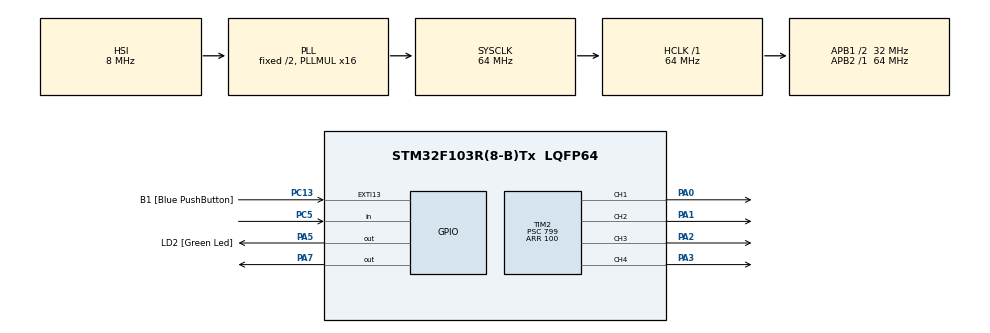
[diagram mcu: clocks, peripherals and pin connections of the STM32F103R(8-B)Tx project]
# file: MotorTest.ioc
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Mcu.Family=STM32F1
TIM2.Channel-PWM\ Generation4\ CH4=TIM_CHANNEL_4
PA14.GPIO_Label=TCK
PC13-TAMPER-RTC.Signal=GPXTI13
TIM2.Channel-PWM\ Generation2\ CH2=TIM_CHANNEL_2
RCC.APB1CLKDivider=RCC_HCLK_DIV2
RCC.SYSCLKSource=RCC_SYSCLKSOURCE_PLLCLK
ProjectManager.StackSize=0x400
PA0-WKUP.Signal=S_TIM2_CH1_ETR
TIM2.Pulse-PWM\ Generation1\ CH1=60
PA13.Signal=SYS_JTMS-SWDIO
SH.S_TIM2_CH2.0=TIM2_CH2,PWM Generation2 CH2
ProjectManager.TargetToolchain=STM32CubeIDE
RCC.HCLKFreq_Value=64000000
RCC.APB2TimFreq_Value=64000000
RCC.USBFreq_Value=64000000
PA1.Signal=S_TIM2_CH2
RCC.AHBFreq_Value=64000000
NVIC.EXTI15_10_IRQn=true\:0\:0\:false\:false\:true\:true\:true
PA5.Signal=GPIO_Output
board=NUCLEO-F103RB
RCC.RTCClockSelection=RCC_RTCCLKSOURCE_LSE
PC13-TAMPER-RTC.GPIO_Label=B1 [Blue PushButton]
RCC.PLLMUL=RCC_PLL_MUL16
RCC.APB2Freq_Value=64000000
PA5.GPIO_ModeDefaultOutputPP=GPIO_MODE_OUTPUT_PP
VP_TIM2_VS_ClockSourceINT.Mode=Internal
SH.S_TIM2_CH3.0=TIM2_CH3,PWM Generation3 CH3
PA14.Mode=Serial_Wire
PA5.GPIO_PuPd=GPIO_NOPULL
TIM2.Channel-PWM\ Generation3\ CH3=TIM_CHANNEL_3
TIM2.Channel-PWM\ Generation1\ CH1=TIM_CHANNEL_1
TIM2.Period=100
PA13.Mode=Serial_Wire
Mcu.Name=STM32F103R(8-B)Tx
PA2.Signal=S_TIM2_CH3
PA13.GPIO_Label=TMS
RCC.SYSCLKFreq_VALUE=64000000
Mcu.Package=LQFP64
TIM2.Prescaler=799
PA5.GPIO_Label=LD2 [Green Led]
PC13-TAMPER-RTC.GPIO_PuPd=GPIO_NOPULL
SH.S_TIM2_CH1_ETR.0=TIM2_CH1,PWM Generation1 CH1
PA14.Signal=SYS_JTCK-SWCLK
ProjectManager.HeapSize=0x200
SH.S_TIM2_CH4.0=TIM2_CH4,PWM Generation4 CH4
TIM2.Pulse-PWM\ Generation2\ CH2=60
PA5.GPIO_Speed=GPIO_SPEED_FREQ_LOW
NVIC.PriorityGroup=NVIC_PRIORITYGROUP_4
RCC.APB1TimFreq_Value=64000000
PC5.Signal=GPIO_Input
RCC.APB1Freq_Value=32000000
PA3.Signal=S_TIM2_CH4
PA7.Signal=GPIO_Output

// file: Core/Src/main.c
/* USER CODE BEGIN Header */
/**
  ******************************************************************************
  * @file           : main.c
  * @brief          : Main program body
  ******************************************************************************
  * @attention
  *
  * <h2><center>&copy; Copyright (c) 2021 STMicroelectronics.
  * All rights reserved.</center></h2>
  *
  * This software component is licensed by ST under BSD 3-Clause license,
  * the "License"; You may not use this file except in compliance with the
  * License. You may obtain a copy of the License at:
  *                        opensource.org/licenses/BSD-3-Clause
  *
  ******************************************************************************
  */
/* USER CODE END Header */
#include "main.h"

TIM_HandleTypeDef htim2;

void SystemClock_Config(void);
static void MX_GPIO_Init(void);
static void MX_TIM2_Init(void);
/* USER CODE BEGIN PFP */
void Delay(uint32_t count);
/* USER CODE END PFP */

int main(void)
{

  /* MCU Configuration--------------------------------------------------------*/

  /* Reset of all peripherals, Initializes the Flash interface and the Systick. */
  HAL_Init();

  /* Configure the system clock */
  SystemClock_Config();

  /* Initialize all configured peripherals */
  MX_GPIO_Init();
  MX_TIM2_Init();
  /* USER CODE BEGIN 2 */
//  HAL_TIM_PWM_Start(&htim2,1);
//  HAL_Delay(100);
//  HAL_TIM_PWM_Start(&htim2,2);
//  HAL_TIM_PWM_Start(&htim2,3);
//  HAL_TIM_PWM_Start(&htim2,4);
  uint32_t count=0;
  uint32_t counter=0;
  uint8_t read=0;
  /* USER CODE END 2 */

  /* Infinite loop */
  while (1)
  {
	  if(counter==0)
	  {
		  HAL_GPIO_WritePin(GPIOA, GPIO_PIN_7, GPIO_PIN_SET);
		  Delay(60);
		  HAL_GPIO_WritePin(GPIOA, GPIO_PIN_7, GPIO_PIN_RESET);
		  counter++;
	  }

	  if( HAL_GPIO_ReadPin(GPIOC,GPIO_PIN_5))
	  {
		  read=1;
	  }
	  while(read==1)
	  {
		  Delay(10);
		  if( HAL_GPIO_ReadPin(GPIOC,GPIO_PIN_5))
		  	  {
		  		  read=1;
		  		  count++;
		  	  }
		  else
		  {
			  read=0;
		  }
	  }

  }
}

void SystemClock_Config(void)
{
  RCC_OscInitTypeDef RCC_OscInitStruct = {0};
  RCC_ClkInitTypeDef RCC_ClkInitStruct = {0};

  /** Initializes the RCC Oscillators according to the specified parameters
  * in the RCC_OscInitTypeDef structure.
  */
  RCC_OscInitStruct.OscillatorType = RCC_OSCILLATORTYPE_HSI;
  RCC_OscInitStruct.HSIState = RCC_HSI_ON;
  RCC_OscInitStruct.HSICalibrationValue = RCC_HSICALIBRATION_DEFAULT;
  RCC_OscInitStruct.PLL.PLLState = RCC_PLL_ON;
  RCC_OscInitStruct.PLL.PLLSource = RCC_PLLSOURCE_HSI_DIV2;
  RCC_OscInitStruct.PLL.PLLMUL = RCC_PLL_MUL16;
  if (HAL_RCC_OscConfig(&RCC_OscInitStruct) != HAL_OK)
  {
    Error_Handler();
  }
  /** Initializes the CPU, AHB and APB buses clocks
  */
  RCC_ClkInitStruct.ClockType = RCC_CLOCKTYPE_HCLK|RCC_CLOCKTYPE_SYSCLK
                              |RCC_CLOCKTYPE_PCLK1|RCC_CLOCKTYPE_PCLK2;
  RCC_ClkInitStruct.SYSCLKSource = RCC_SYSCLKSOURCE_PLLCLK;
  RCC_ClkInitStruct.AHBCLKDivider = RCC_SYSCLK_DIV1;
  RCC_ClkInitStruct.APB1CLKDivider = RCC_HCLK_DIV2;
  RCC_ClkInitStruct.APB2CLKDivider = RCC_HCLK_DIV1;

  if (HAL_RCC_ClockConfig(&RCC_ClkInitStruct, FLASH_LATENCY_2) != HAL_OK)
  {
    Error_Handler();
  }
}

static void MX_TIM2_Init(void)
{

  TIM_ClockConfigTypeDef sClockSourceConfig = {0};
  TIM_MasterConfigTypeDef sMasterConfig = {0};
  TIM_OC_InitTypeDef sConfigOC = {0};

  htim2.Instance = TIM2;
  htim2.Init.Prescaler = 79;
  htim2.Init.CounterMode = TIM_COUNTERMODE_UP;
  htim2.Init.Period = 100;
  htim2.Init.ClockDivision = TIM_CLOCKDIVISION_DIV1;
  htim2.Init.AutoReloadPreload = TIM_AUTORELOAD_PRELOAD_DISABLE;
  if (HAL_TIM_Base_Init(&htim2) != HAL_OK)
  {
    Error_Handler();
  }
  sClockSourceConfig.ClockSource = TIM_CLOCKSOURCE_INTERNAL;
  if (HAL_TIM_ConfigClockSource(&htim2, &sClockSourceConfig) != HAL_OK)
  {
    Error_Handler();
  }
  if (HAL_TIM_PWM_Init(&htim2) != HAL_OK)
  {
    Error_Handler();
  }
  sMasterConfig.MasterOutputTrigger = TIM_TRGO_RESET;
  sMasterConfig.MasterSlaveMode = TIM_MASTERSLAVEMODE_DISABLE;
  if (HAL_TIMEx_MasterConfigSynchronization(&htim2, &sMasterConfig) != HAL_OK)
  {
    Error_Handler();
  }
  sConfigOC.OCMode = TIM_OCMODE_PWM1;
  sConfigOC.Pulse = 60;
  sConfigOC.OCPolarity = TIM_OCPOLARITY_HIGH;
  sConfigOC.OCFastMode = TIM_OCFAST_DISABLE;
  if (HAL_TIM_PWM_ConfigChannel(&htim2, &sConfigOC, TIM_CHANNEL_1) != HAL_OK)
  {
    Error_Handler();
  }
  if (HAL_TIM_PWM_ConfigChannel(&htim2, &sConfigOC, TIM_CHANNEL_2) != HAL_OK)
  {
    Error_Handler();
  }
  sConfigOC.Pulse = 0;
  if (HAL_TIM_PWM_ConfigChannel(&htim2, &sConfigOC, TIM_CHANNEL_3) != HAL_OK)
  {
    Error_Handler();
  }
  if (HAL_TIM_PWM_ConfigChannel(&htim2, &sConfigOC, TIM_CHANNEL_4) != HAL_OK)
  {
    Error_Handler();
  }
  HAL_TIM_MspPostInit(&htim2);

}

static void MX_GPIO_Init(void)
{
  GPIO_InitTypeDef GPIO_InitStruct = {0};

  /* GPIO Ports Clock Enable */
  __HAL_RCC_GPIOC_CLK_ENABLE();
  __HAL_RCC_GPIOA_CLK_ENABLE();

  /*Configure GPIO pin Output Level */
  HAL_GPIO_WritePin(GPIOA, LD2_Pin|GPIO_PIN_7, GPIO_PIN_RESET);

  /*Configure GPIO pin : B1_Pin */
  GPIO_InitStruct.Pin = B1_Pin;
  GPIO_InitStruct.Mode = GPIO_MODE_IT_RISING;
  GPIO_InitStruct.Pull = GPIO_NOPULL;
  HAL_GPIO_Init(B1_GPIO_Port, &GPIO_InitStruct);

  /*Configure GPIO pins : LD2_Pin PA7 */
  GPIO_InitStruct.Pin = LD2_Pin|GPIO_PIN_7;
  GPIO_InitStruct.Mode = GPIO_MODE_OUTPUT_PP;
  GPIO_InitStruct.Pull = GPIO_NOPULL;
  GPIO_InitStruct.Speed = GPIO_SPEED_FREQ_LOW;
  HAL_GPIO_Init(GPIOA, &GPIO_InitStruct);

  /*Configure GPIO pin : PC5 */
  GPIO_InitStruct.Pin = GPIO_PIN_5;
  GPIO_InitStruct.Mode = GPIO_MODE_INPUT;
  GPIO_InitStruct.Pull = GPIO_NOPULL;
  HAL_GPIO_Init(GPIOC, &GPIO_InitStruct);

  /* EXTI interrupt init*/
  HAL_NVIC_SetPriority(EXTI15_10_IRQn, 0, 0);
  HAL_NVIC_EnableIRQ(EXTI15_10_IRQn);

}

/* USER CODE BEGIN 4 */
void Delay(uint32_t count)
{
	for(int i=0;i<count;i++)
	{

	}
}
/* USER CODE END 4 */

void Error_Handler(void)
{
  __disable_irq();
  while (1)
  {
  }
}

/************************ (C) COPYRIGHT STMicroelectronics *****END OF FILE****/
